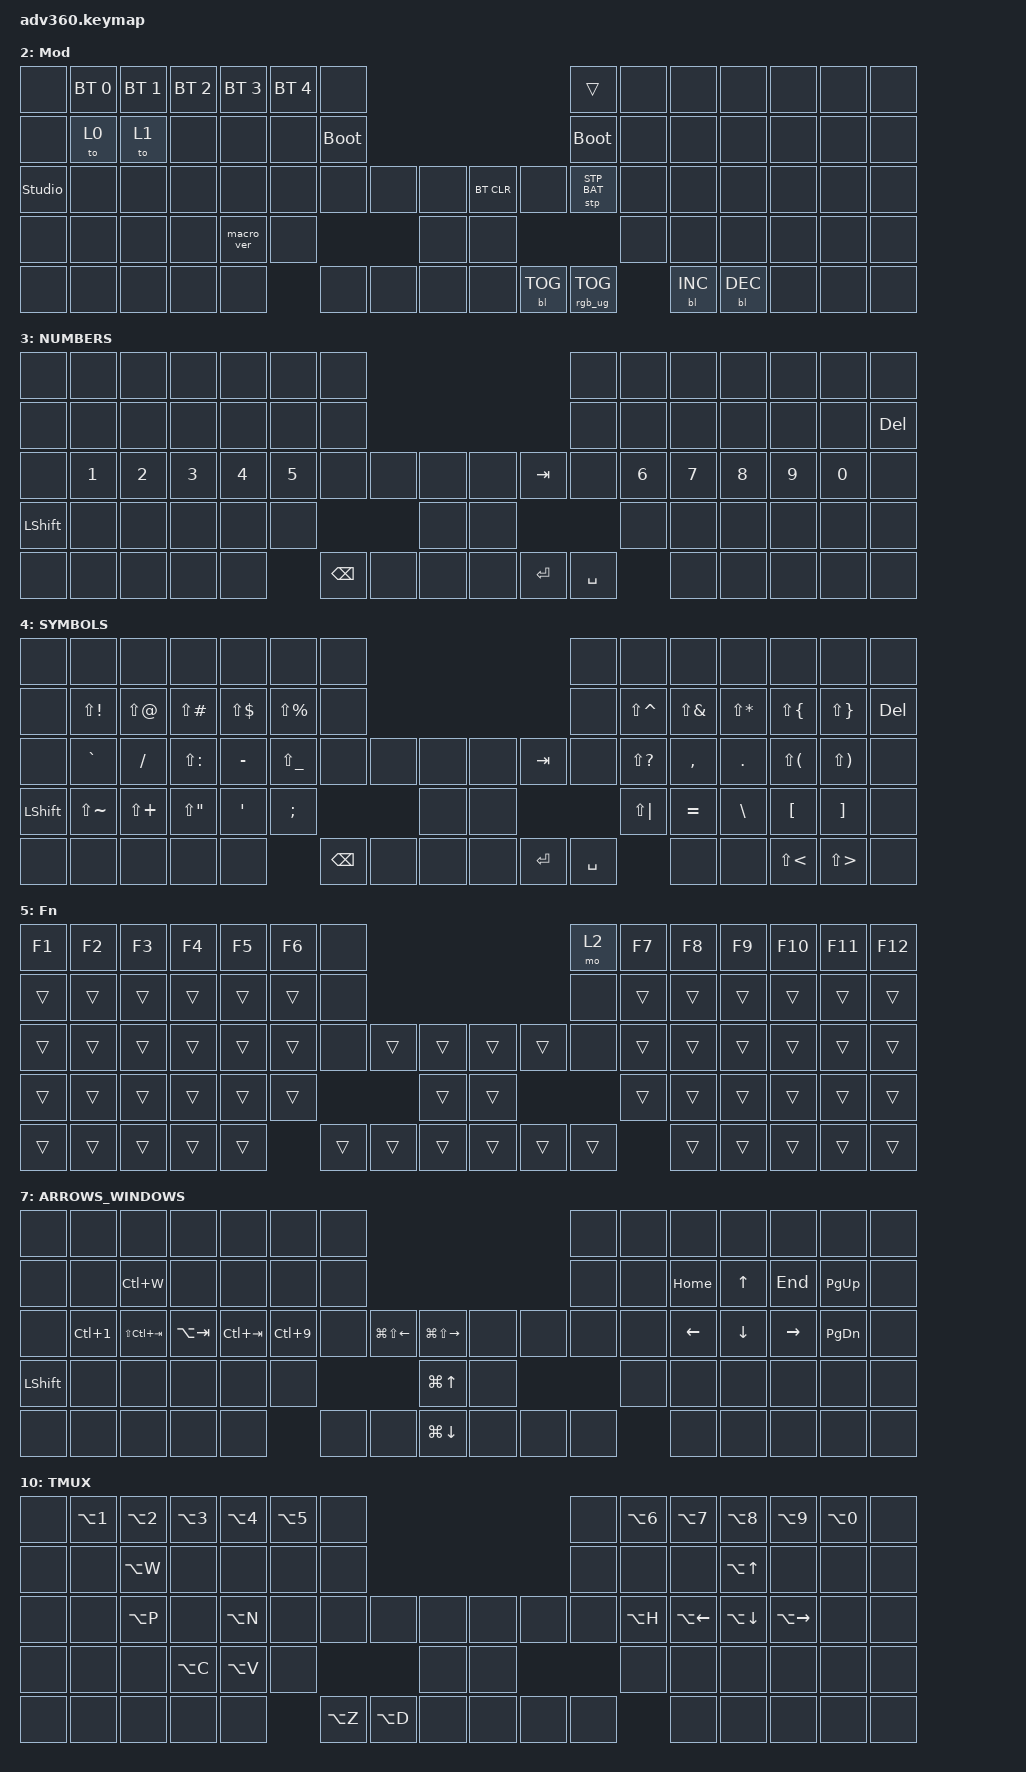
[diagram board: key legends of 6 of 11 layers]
#include <dt-bindings/zmk/stp.h>
#include <behaviors.dtsi>
#include <dt-bindings/zmk/backlight.h>
#include <dt-bindings/zmk/bt.h>
#include <dt-bindings/zmk/keys.h>
#include <dt-bindings/zmk/rgb.h>

&lt {
    quick-tap-ms = <175>;
    hold-trigger-on-release;
};

/ {
    behaviors {
        #include "macros.dtsi"
      #include "version.dtsi"

        hm: homerow_mods {
            compatible = "zmk,behavior-hold-tap";
            label = "HOMEROW_MODS";
            #binding-cells = <2>;
            tapping-term-ms = <200>;
            quick_tap_ms = <175>;
            flavor = "tap-preferred";
            bindings = <&kp>, <&kp>;

            hold-trigger-on-release;
            require-prior-idle-ms = <150>;
            quick-tap-ms = <175>;
        };
    };

    macros {
        tmux_previous_window: tmux_previous_window {
            compatible = "zmk,behavior-macro";
            #binding-cells = <0>;
            bindings =
                <&macro_tap>,
                <&kp LC(B)>,
                <&macro_wait_time 30>,
                <&macro_tap>,
                <&kp P>;

            label = "TMUX_PREVIOUS_WINDOW";
        };

        tmux_next_window: tmux_next_window {
            compatible = "zmk,behavior-macro";
            #binding-cells = <0>;
            bindings =
                <&macro_tap>,
                <&kp LC(B)>,
                <&macro_wait_time 30>,
                <&macro_tap>,
                <&kp N>;

            label = "TMUX_NEXT_WINDOW";
        };
    };

    keymap {
        compatible = "zmk,keymap";

        DEFAULT_MACOS {
            display-name = "Base";
            bindings = <
&kp C_VOLUME_UP    &kp N1     &kp N2     &kp N3     &kp N4     &kp N5  &mo 2                                                                                         &mo 2        &kp N6  &kp N7     &kp N8  &kp N9  &kp N0  &kp LC(LG(Q))
&kp C_VOLUME_DOWN  &kp Q      &kp W      &kp E      &kp R      &kp T   &none                                                                                         &none        &kp Y   &kp U      &kp I   &kp O   &kp P   &kp DEL
&none              &kp A      &kp S      &kp D      &kp F      &kp G   &none     &lt (8) LA(LC(LEFT_GUI))  &lt 9 ESCAPE      &kp LEFT_ALT      &mt LEFT_COMMAND TAB  &none        &kp H   &kp J      &kp K   &kp L   &none   &none
&kp LSHFT          &kp Z      &kp X      &kp C      &kp V      &kp B                                       &kp LC(C)         &kp LEFT_CONTROL                                     &kp N   &kp M      &none   &none   &none   &none
&lt (5) LC(SPACE)  &kp LG(Z)  &kp LG(X)  &kp LG(C)  &kp LG(V)          &kp BSPC  &mo 4                     &mo 3             &mo 10            &kp ENTER             &lt 6 SPACE          &kp LG(F)  &none   &none   &none   &none
            >;
        };

        DEFAULT_WINDOWS {
            bindings = <
&trans                  &trans     &trans     &trans     &trans     &trans  &trans                                                          &trans       &trans  &trans     &trans  &trans  &trans  &kp LG(L)
&trans                  &trans     &trans     &trans     &trans     &trans  &trans                                                          &trans       &trans  &trans     &trans  &trans  &trans  &trans
&trans                  &trans     &trans     &trans     &trans     &trans  &trans  &trans  &trans      &trans        &mt LEFT_CONTROL TAB  &trans       &trans  &trans     &trans  &trans  &trans  &trans
&trans                  &trans     &trans     &trans     &trans     &trans                  &trans      &kp LEFT_GUI                                     &trans  &trans     &trans  &trans  &trans  &trans
&lt (5) LA(LEFT_SHIFT)  &kp LC(Z)  &kp LC(X)  &kp LC(C)  &kp LC(V)          &trans  &trans  &trans      &trans        &trans                &lt 7 SPACE          &kp LC(F)  &trans  &trans  &trans  &trans
            >;
        };

        mod {
            display-name = "Mod";
            bindings = <
&none           &bt BT_SEL 0  &bt BT_SEL 1  &bt BT_SEL 2  &bt BT_SEL 3  &bt BT_SEL 4  &none                                                  &trans           &none  &none       &none       &none  &none  &none
&none           &to 0         &to 1         &none         &none         &none         &bootloader                                            &bootloader      &none  &none       &none       &none  &none  &none
&studio_unlock  &none         &none         &none         &none         &none         &none        &none  &none      &bt BT_CLR  &none       &stp STP_BAT     &none  &none       &none       &none  &none  &none
&none           &none         &none         &none         &macro_ver    &none                             &none      &none                                    &none  &none       &none       &none  &none  &none
&none           &none         &none         &none         &none                       &none        &none  &none      &none       &bl BL_TOG  &rgb_ug RGB_TOG         &bl BL_INC  &bl BL_DEC  &none  &none  &none
            >;
        };

        NUMBERS {
            bindings = <
&none           &none   &none   &none   &none   &none   &none                                       &none      &none   &none   &none   &none   &none   &none
&none           &none   &none   &none   &none   &none   &none                                       &none      &none   &none   &none   &none   &none   &kp DEL
&none           &kp N1  &kp N2  &kp N3  &kp N4  &kp N5  &none     &none  &none      &none  &kp TAB  &none      &kp N6  &kp N7  &kp N8  &kp N9  &kp N0  &none
&kp LEFT_SHIFT  &none   &none   &none   &none   &none                    &none      &none                      &none   &none   &none   &none   &none   &none
&none           &none   &none   &none   &none           &kp BSPC  &none  &none      &none  &kp RET  &kp SPACE          &none   &none   &none   &none   &none
            >;
        };

        SYMBOLS {
            bindings = <
&none      &none          &none         &none          &none         &none          &none                                         &none      &none          &none         &none         &none         &none         &none
&none      &kp LS(EXCL)   &kp LS(AT)    &kp LS(POUND)  &kp LS(DLLR)  &kp LS(PRCNT)  &none                                         &none      &kp LS(CARET)  &kp LS(AMPS)  &kp LS(STAR)  &kp LS(LBRC)  &kp LS(RBRC)  &kp DELETE
&none      &kp GRAVE      &kp FSLH      &kp LS(COLON)  &kp MINUS     &kp LS(UNDER)  &none     &none  &none      &none  &kp TAB    &none      &kp LS(QMARK)  &kp COMMA     &kp DOT       &kp LS(LPAR)  &kp LS(RPAR)  &none
&kp LSHFT  &kp LS(TILDE)  &kp LS(PLUS)  &kp LS(DQT)    &kp SQT       &kp SEMI                        &none      &none                        &kp LS(PIPE)   &kp EQUAL     &kp BSLH      &kp LBKT      &kp RBKT      &none
&none      &none          &none         &none          &none                        &kp BSPC  &none  &none      &none  &kp ENTER  &kp SPACE                 &none         &none         &kp LS(LT)    &kp LS(GT)    &none
            >;
        };

        fn {
            display-name = "Fn";
            bindings = <
&kp F1  &kp F2  &kp F3  &kp F4  &kp F5  &kp F6  &none                                       &mo 2   &kp F7  &kp F8  &kp F9  &kp F10  &kp F11  &kp F12
&trans  &trans  &trans  &trans  &trans  &trans  &none                                       &none   &trans  &trans  &trans  &trans   &trans   &trans
&trans  &trans  &trans  &trans  &trans  &trans  &none   &trans  &trans      &trans  &trans  &none   &trans  &trans  &trans  &trans   &trans   &trans
&trans  &trans  &trans  &trans  &trans  &trans                  &trans      &trans                  &trans  &trans  &trans  &trans   &trans   &trans
&trans  &trans  &trans  &trans  &trans          &trans  &trans  &trans      &trans  &trans  &trans          &trans  &trans  &trans   &trans   &trans
            >;
        };

        ARROWS {
            bindings = <
&none      &none             &none            &none          &none        &none       &none                                                                    &none  &none  &none           &none           &none            &none          &none
&none      &none             &kp LG(W)        &none          &none        &none       &none                                                                    &none  &none  &kp HOME        &kp UP_ARROW    &kp END          &kp PAGE_UP    &none
&none      &kp LG(NUMBER_1)  &kp LS(LC(TAB))  &kp LG(GRAVE)  &kp LC(TAB)  &kp LG(N9)  &none  &kp LS(LA(LG(LEFT)))  &kp LS(LA(LG(RIGHT)))         &none  &none  &none  &none  &kp LEFT_ARROW  &kp DOWN_ARROW  &kp RIGHT_ARROW  &kp PAGE_DOWN  &none
&kp LSHFT  &none             &none            &none          &none        &none                                    &kp LS(LA(LG(UP_ARROW)))      &none                &none  &none           &none           &none            &none          &none
&none      &none             &none            &none          &none                    &none  &none                 &kp LS(LA(LG(DOWN)))          &none  &none  &none         &none           &none           &none            &none          &none
            >;
        };

        ARROWS_WINDOWS {
            bindings = <
&none           &none             &none            &none        &none        &none       &none                                                         &none  &none  &none     &none     &none      &none          &none
&none           &none             &kp LC(W)        &none        &none        &none       &none                                                         &none  &none  &kp HOME  &kp UP    &kp END    &kp PAGE_UP    &none
&none           &kp LC(NUMBER_1)  &kp LS(LC(TAB))  &kp LA(TAB)  &kp LC(TAB)  &kp LC(N9)  &none  &kp LG(LS(LEFT))  &kp LG(LS(RIGHT))      &none  &none  &none  &none  &kp LEFT  &kp DOWN  &kp RIGHT  &kp PAGE_DOWN  &none
&kp LEFT_SHIFT  &none             &none            &none        &none        &none                                &kp LG(UP)             &none                &none  &none     &none     &none      &none          &none
&none           &none             &none            &none        &none                    &none  &none             &kp LG(DOWN)           &none  &none  &none         &none     &none     &none      &none          &none
            >;
        };

        LAUNCHER {
            bindings = <
&none  &kp RS(RA(RC(RG(N1))))  &kp RS(RA(RC(RG(N2))))  &kp RS(RA(RC(RG(N3))))  &kp RS(RA(RC(RG(N4))))  &kp RS(RA(RC(RG(N5))))  &none                                  &none  &kp RS(RA(RC(RG(N6))))  &kp RS(RA(RC(RG(N7))))  &kp RS(RA(RC(RG(N8))))  &kp RS(RA(RC(RG(N9))))  &kp RS(RA(RC(RG(N0))))  &none
&none  &kp RS(RC(RG(RA(Q))))   &kp RS(RA(RC(RG(W))))   &kp RS(RA(RC(RG(E))))   &kp RS(RA(RC(RG(R))))   &kp RS(RA(RC(RG(T))))   &none                                  &none  &kp RS(RA(RC(RG(Y))))   &kp RS(RA(RC(RG(U))))   &kp RS(RA(RC(RG(I))))   &kp RS(RC(RA(RG(O))))   &kp RS(RC(RA(RG(P))))   &none
&none  &kp RS(RA(RC(RG(A))))   &kp RA(RC(RS(RG(S))))   &kp RS(RA(RC(RG(D))))   &kp RS(RA(RC(RG(F))))   &kp RS(RG(RA(RC(G))))   &none  &none  &none      &none  &none  &none  &kp RS(RA(RC(RG(H))))   &kp RS(RA(RC(RG(J))))   &kp RS(RA(RC(RG(K))))   &kp RS(RA(RC(RG(L))))   &none                   &none
&none  &kp RC(RA(RS(RG(Z))))   &kp RS(RA(RC(RG(X))))   &kp RS(RA(RC(RG(C))))   &kp RS(RA(RC(RG(V))))   &kp RS(RA(RC(RG(B))))                 &none      &none                &kp RS(RA(RC(RG(N))))   &kp RS(RA(RC(RG(M))))   &none                   &none                   &none                   &none
&none  &none                   &none                   &none                   &none                                           &none  &none  &none      &none  &none  &none                          &none                   &none                   &none                   &none                   &none
            >;
        };

        LAUNCHER_PREFILL {
            bindings = <
&none  &kp RS(RA(RC(LG(N1))))  &kp RS(RA(RC(LG(N2))))  &kp RS(RA(RC(LG(N3))))  &kp RS(RA(RC(LG(N4))))  &kp RS(RA(RC(LG(N5))))  &none                                  &none  &kp RS(RA(RC(LG(N6))))  &kp RS(RA(RC(LG(N7))))  &kp RS(RA(RC(LG(N8))))  &kp RS(RA(RC(LG(N9))))  &kp RS(RA(RC(LG(N0))))  &none
&none  &kp RS(RC(RA(LG(Q))))   &kp RS(RA(RC(LG(W))))   &kp RS(RA(RC(LG(E))))   &kp RS(RA(RC(LG(R))))   &kp RS(RA(RC(LG(T))))   &none                                  &none  &kp RS(RA(RC(LG(Y))))   &kp RS(RA(RC(LG(U))))   &kp RS(RA(RC(LG(I))))   &kp RS(RC(RA(LG(O))))   &kp RS(RC(RA(LG(P))))   &none
&none  &kp RS(RA(RC(LG(A))))   &kp RA(RC(RS(LG(S))))   &kp RS(RA(RC(LG(D))))   &kp RS(RA(RC(LG(F))))   &kp RS(RA(RC(LG(G))))   &none  &none  &none      &none  &none  &none  &kp RS(RA(RC(LG(H))))   &kp RS(RA(RC(LG(J))))   &kp RS(RA(RC(LG(K))))   &kp RS(RA(RC(LG(L))))   &none                   &none
&none  &kp RC(RA(RS(LG(Z))))   &kp RS(RA(RC(LG(X))))   &kp RS(RA(RC(LG(C))))   &kp RS(RA(RC(LG(V))))   &kp RS(RA(RC(LG(B))))                 &none      &none                &kp RS(RA(RC(LG(N))))   &kp RS(RA(RC(LG(M))))   &none                   &none                   &none                   &none
&none  &none                   &none                   &none                   &none                                           &none  &none  &none      &none  &none  &none                          &none                   &none                   &none                   &none                   &none
            >;
        };

        TMUX {
            bindings = <
&none  &kp LA(N1)  &kp LA(N2)  &kp LA(N3)  &kp LA(N4)  &kp LA(N5)  &none                                          &none  &kp LA(N6)  &kp LA(N7)    &kp LA(N8)    &kp LA(N9)     &kp LA(N0)  &none
&none  &none       &kp LA(W)   &none       &none       &none       &none                                          &none  &none       &none         &kp LA(UP)    &none          &none       &none
&none  &none       &kp LA(P)   &none       &kp LA(N)   &none       &none      &none      &none      &none  &none  &none  &kp LA(H)   &kp LA(LEFT)  &kp LA(DOWN)  &kp LA(RIGHT)  &none       &none
&none  &none       &none       &kp LA(C)   &kp LA(V)   &none                             &none      &none                &none       &none         &none         &none          &none       &none
&none  &none       &none       &none       &none                   &kp LA(Z)  &kp LA(D)  &none      &none  &none  &none              &none         &none         &none          &none       &none
            >;
        };
    };
};
